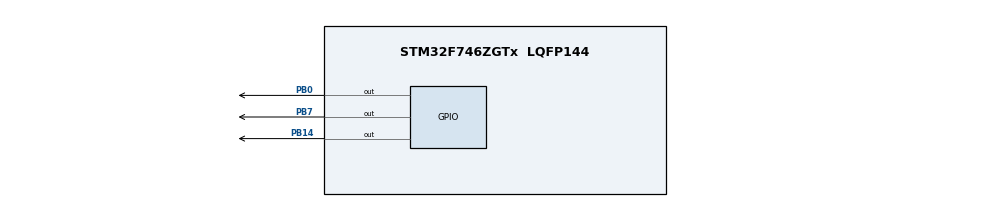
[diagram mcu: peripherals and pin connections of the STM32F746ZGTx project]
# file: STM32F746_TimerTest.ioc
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Mcu.Family=STM32F7
TIM1.Channel-Output\ Compare1\ No\ Output=TIM_CHANNEL_1
ProjectManager.StackSize=0x400
VP_TIM1_VS_no_output1.Mode=Output Compare1 No Output
TIM1.Prescaler=16-1
ProjectManager.TargetToolchain=STM32CubeIDE
RCC.APB2TimFreq_Value=2000000
RCC.USBFreq_Value=96000000
RCC.LSE_VALUE=32768
PB14.Signal=GPIO_Output
RCC.HSE_VALUE=25000000
board=custom
RCC.VCOOutputFreq_Value=192000000
RCC.APB2Freq_Value=1000000
PB7.Signal=GPIO_Output
Mcu.Name=STM32F746ZGTx
VP_TIM1_VS_ClockSourceINT.Mode=Internal
NVIC.TIM1_CC_IRQn=true\:0\:0\:false\:false\:true\:true\:true
Mcu.Package=LQFP144
TIM1.Pulse-Output\ Compare1\ No\ Output=2000-1
ProjectManager.HeapSize=0x200
RCC.HSI_VALUE=16000000
NVIC.PriorityGroup=NVIC_PRIORITYGROUP_4
RCC.APB2CLKDivider=RCC_HCLK_DIV16
PB0.Signal=GPIO_Output

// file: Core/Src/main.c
/* USER CODE BEGIN Header */
/**
  ******************************************************************************
  * @file           : main.c
  * @brief          : Main program body
  ******************************************************************************
  * @attention
  *
  * <h2><center>&copy; Copyright (c) 2021 STMicroelectronics.
  * All rights reserved.</center></h2>
  *
  * This software component is licensed by ST under BSD 3-Clause license,
  * the "License"; You may not use this file except in compliance with the
  * License. You may obtain a copy of the License at:
  *                        opensource.org/licenses/BSD-3-Clause
  *
  ******************************************************************************
  */
/* USER CODE END Header */
#include "main.h"

TIM_HandleTypeDef htim1;

void SystemClock_Config(void);
static void MX_GPIO_Init(void);
static void MX_TIM1_Init(void);

/* USER CODE BEGIN 0 */
unsigned int counter = 0;
void HAL_TIM_OC_DelayElapsedCallback(TIM_HandleTypeDef *htim){
	HAL_TIM_OC_Stop_IT(&htim1, TIM_CHANNEL_1);
	HAL_GPIO_TogglePin(GPIOB, GPIO_PIN_7);
	if((htim->Instance == TIM1) && (htim->Channel == HAL_TIM_ACTIVE_CHANNEL_1)){
		HAL_GPIO_TogglePin(GPIOB, GPIO_PIN_0);
		__HAL_TIM_SET_COUNTER(&htim1, 0);
	}
	counter++;
	__HAL_TIM_SET_COMPARE(&htim1, TIM_CHANNEL_1, (counter)+2-1 );
	HAL_TIM_OC_Start_IT(&htim1, TIM_CHANNEL_1);
}
/* USER CODE END 0 */

int main(void)
{

  /* MCU Configuration--------------------------------------------------------*/

  /* Reset of all peripherals, Initializes the Flash interface and the Systick. */
  HAL_Init();

  /* Configure the system clock */
  SystemClock_Config();

  /* Initialize all configured peripherals */
  MX_GPIO_Init();
  MX_TIM1_Init();
  /* USER CODE BEGIN 2 */
  HAL_TIM_OC_Start_IT(&htim1, TIM_CHANNEL_1);
  /* USER CODE END 2 */

  /* Infinite loop */
  while (1)
  {

    /* USER CODE BEGIN 3 */
	  HAL_GPIO_TogglePin(GPIOB, GPIO_PIN_14);
	  HAL_Delay(500);
  }
  /* USER CODE END 3 */
}

void SystemClock_Config(void)
{
  RCC_OscInitTypeDef RCC_OscInitStruct = {0};
  RCC_ClkInitTypeDef RCC_ClkInitStruct = {0};

  /** Configure the main internal regulator output voltage
  */
  __HAL_RCC_PWR_CLK_ENABLE();
  __HAL_PWR_VOLTAGESCALING_CONFIG(PWR_REGULATOR_VOLTAGE_SCALE3);
  /** Initializes the RCC Oscillators according to the specified parameters
  * in the RCC_OscInitTypeDef structure.
  */
  RCC_OscInitStruct.OscillatorType = RCC_OSCILLATORTYPE_HSI;
  RCC_OscInitStruct.HSIState = RCC_HSI_ON;
  RCC_OscInitStruct.HSICalibrationValue = RCC_HSICALIBRATION_DEFAULT;
  RCC_OscInitStruct.PLL.PLLState = RCC_PLL_NONE;
  if (HAL_RCC_OscConfig(&RCC_OscInitStruct) != HAL_OK)
  {
    Error_Handler();
  }
  /** Initializes the CPU, AHB and APB buses clocks
  */
  RCC_ClkInitStruct.ClockType = RCC_CLOCKTYPE_HCLK|RCC_CLOCKTYPE_SYSCLK
                              |RCC_CLOCKTYPE_PCLK1|RCC_CLOCKTYPE_PCLK2;
  RCC_ClkInitStruct.SYSCLKSource = RCC_SYSCLKSOURCE_HSI;
  RCC_ClkInitStruct.AHBCLKDivider = RCC_SYSCLK_DIV1;
  RCC_ClkInitStruct.APB1CLKDivider = RCC_HCLK_DIV1;
  RCC_ClkInitStruct.APB2CLKDivider = RCC_HCLK_DIV16;

  if (HAL_RCC_ClockConfig(&RCC_ClkInitStruct, FLASH_LATENCY_0) != HAL_OK)
  {
    Error_Handler();
  }
}

static void MX_TIM1_Init(void)
{

  TIM_ClockConfigTypeDef sClockSourceConfig = {0};
  TIM_MasterConfigTypeDef sMasterConfig = {0};
  TIM_OC_InitTypeDef sConfigOC = {0};
  TIM_BreakDeadTimeConfigTypeDef sBreakDeadTimeConfig = {0};

  htim1.Instance = TIM1;
  htim1.Init.Prescaler = 20000-1;
  htim1.Init.CounterMode = TIM_COUNTERMODE_UP;
  htim1.Init.Period = 65535;
  htim1.Init.ClockDivision = TIM_CLOCKDIVISION_DIV1;
  htim1.Init.RepetitionCounter = 0;
  htim1.Init.AutoReloadPreload = TIM_AUTORELOAD_PRELOAD_DISABLE;
  if (HAL_TIM_Base_Init(&htim1) != HAL_OK)
  {
    Error_Handler();
  }
  sClockSourceConfig.ClockSource = TIM_CLOCKSOURCE_INTERNAL;
  if (HAL_TIM_ConfigClockSource(&htim1, &sClockSourceConfig) != HAL_OK)
  {
    Error_Handler();
  }
  if (HAL_TIM_OC_Init(&htim1) != HAL_OK)
  {
    Error_Handler();
  }
  sMasterConfig.MasterOutputTrigger = TIM_TRGO_RESET;
  sMasterConfig.MasterOutputTrigger2 = TIM_TRGO2_RESET;
  sMasterConfig.MasterSlaveMode = TIM_MASTERSLAVEMODE_DISABLE;
  if (HAL_TIMEx_MasterConfigSynchronization(&htim1, &sMasterConfig) != HAL_OK)
  {
    Error_Handler();
  }
  sConfigOC.OCMode = TIM_OCMODE_TIMING;
  sConfigOC.Pulse = 2-1;
  sConfigOC.OCPolarity = TIM_OCPOLARITY_HIGH;
  sConfigOC.OCNPolarity = TIM_OCNPOLARITY_HIGH;
  sConfigOC.OCFastMode = TIM_OCFAST_DISABLE;
  sConfigOC.OCIdleState = TIM_OCIDLESTATE_RESET;
  sConfigOC.OCNIdleState = TIM_OCNIDLESTATE_RESET;
  if (HAL_TIM_OC_ConfigChannel(&htim1, &sConfigOC, TIM_CHANNEL_1) != HAL_OK)
  {
    Error_Handler();
  }
  sBreakDeadTimeConfig.OffStateRunMode = TIM_OSSR_DISABLE;
  sBreakDeadTimeConfig.OffStateIDLEMode = TIM_OSSI_DISABLE;
  sBreakDeadTimeConfig.LockLevel = TIM_LOCKLEVEL_OFF;
  sBreakDeadTimeConfig.DeadTime = 0;
  sBreakDeadTimeConfig.BreakState = TIM_BREAK_DISABLE;
  sBreakDeadTimeConfig.BreakPolarity = TIM_BREAKPOLARITY_HIGH;
  sBreakDeadTimeConfig.BreakFilter = 0;
  sBreakDeadTimeConfig.Break2State = TIM_BREAK2_DISABLE;
  sBreakDeadTimeConfig.Break2Polarity = TIM_BREAK2POLARITY_HIGH;
  sBreakDeadTimeConfig.Break2Filter = 0;
  sBreakDeadTimeConfig.AutomaticOutput = TIM_AUTOMATICOUTPUT_DISABLE;
  if (HAL_TIMEx_ConfigBreakDeadTime(&htim1, &sBreakDeadTimeConfig) != HAL_OK)
  {
    Error_Handler();
  }

}

static void MX_GPIO_Init(void)
{
  GPIO_InitTypeDef GPIO_InitStruct = {0};

  /* GPIO Ports Clock Enable */
  __HAL_RCC_GPIOB_CLK_ENABLE();

  /*Configure GPIO pin Output Level */
  HAL_GPIO_WritePin(GPIOB, GPIO_PIN_0|GPIO_PIN_14|GPIO_PIN_7, GPIO_PIN_RESET);

  /*Configure GPIO pins : PB0 PB14 PB7 */
  GPIO_InitStruct.Pin = GPIO_PIN_0|GPIO_PIN_14|GPIO_PIN_7;
  GPIO_InitStruct.Mode = GPIO_MODE_OUTPUT_PP;
  GPIO_InitStruct.Pull = GPIO_NOPULL;
  GPIO_InitStruct.Speed = GPIO_SPEED_FREQ_LOW;
  HAL_GPIO_Init(GPIOB, &GPIO_InitStruct);

}

void Error_Handler(void)
{
  __disable_irq();
  while (1)
  {
  }
}

/************************ (C) COPYRIGHT STMicroelectronics *****END OF FILE****/
